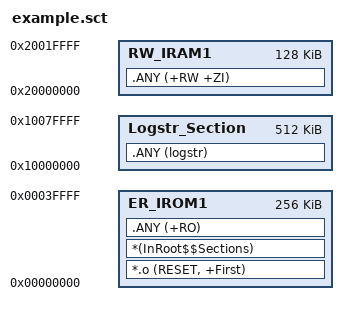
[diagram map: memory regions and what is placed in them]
LR_IROM1 0x00000000 0x00040000  {
  ER_IROM1 0x00000000 0x00040000  {
    *.o (RESET, +First)
    *(InRoot$$Sections)
    .ANY (+RO)
  }
  RW_IRAM1 0x20000000 0x00020000  {
    .ANY (+RW +ZI)
  }
}

LR_LOGSTR 0x10000000 0x00080000  {
  Logstr_Section 0x10000000 0x00080000  {
    .ANY (logstr)
  }
}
